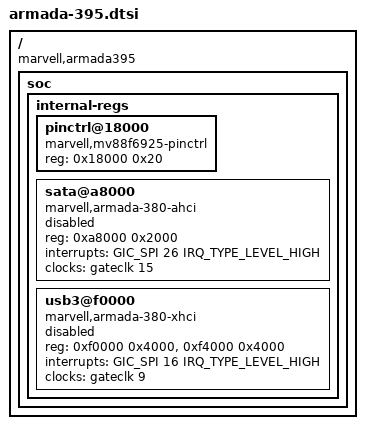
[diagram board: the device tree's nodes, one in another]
// SPDX-License-Identifier: (GPL-2.0+ OR MIT)
/*
 * Device Tree Include file for Marvell Armada 395 SoC.
 *
 * Copyright (C) 2016 Marvell
 *
 * Grzegorz Jaszczyk <jaz@semihalf.com>
 */

#include "armada-39x.dtsi"

/ {
	compatible = "marvell,armada395", "marvell,armada390";

	soc {
		internal-regs {
			pinctrl@18000 {
				compatible = "marvell,mv88f6925-pinctrl";
				reg = <0x18000 0x20>;
			};

			sata@a8000 {
				compatible = "marvell,armada-380-ahci";
				reg = <0xa8000 0x2000>;
				interrupts = <GIC_SPI 26 IRQ_TYPE_LEVEL_HIGH>;
				clocks = <&gateclk 15>;
				status = "disabled";
			};

			usb3@f0000 {
				compatible = "marvell,armada-380-xhci";
				reg = <0xf0000 0x4000>,<0xf4000 0x4000>;
				interrupts = <GIC_SPI 16 IRQ_TYPE_LEVEL_HIGH>;
				clocks = <&gateclk 9>;
				status = "disabled";
			};
		};
	};
};
